# ing916 register map
Vendor: INGChips; Series: ing916xx; File version: 522
CPU: CM4 r0p1, little endian, MPU, FPU, VTOR, 5 interrupt priority bits
Registers are 32-bit, read-write, reset 0x0 unless marked. A register's access mark holds for its fields unless they carry their own. Offsets are from the block's base; [hi:lo] are bit positions; {n}, {i} and the like mark numbered series.

## io_mux_ctrl
Base 0x40006000
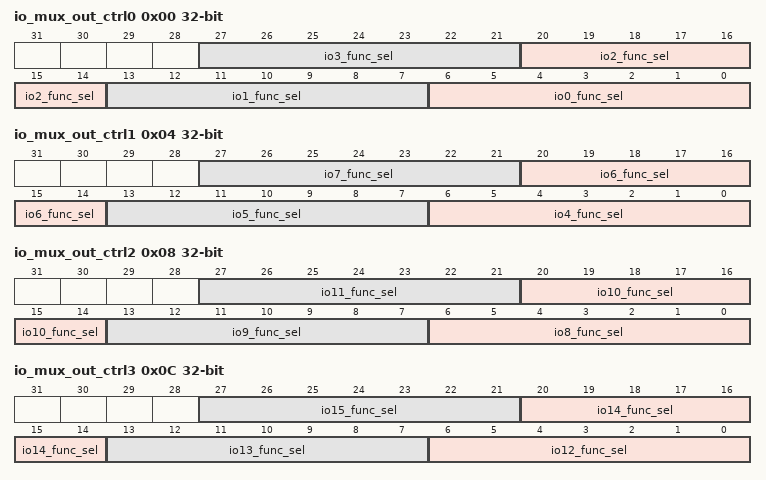
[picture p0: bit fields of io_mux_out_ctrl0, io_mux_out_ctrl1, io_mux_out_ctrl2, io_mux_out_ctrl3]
0x00 io_mux_out_ctrl0 — reg description:
  [7n+6:7n] io{n}_func_sel (n=0..3) — reg description:
0x04 io_mux_out_ctrl1 — reg description:
  [7n-22:7n-28] io{n}_func_sel (n=4..7) — reg description:
0x08 io_mux_out_ctrl2 — reg description:
  [7n-50:7n-56] io{n}_func_sel (n=8..11) — reg description:
0x0C io_mux_out_ctrl3 — reg description:
  [7n-78:7n-84] io{n}_func_sel (n=12..15) — reg description:
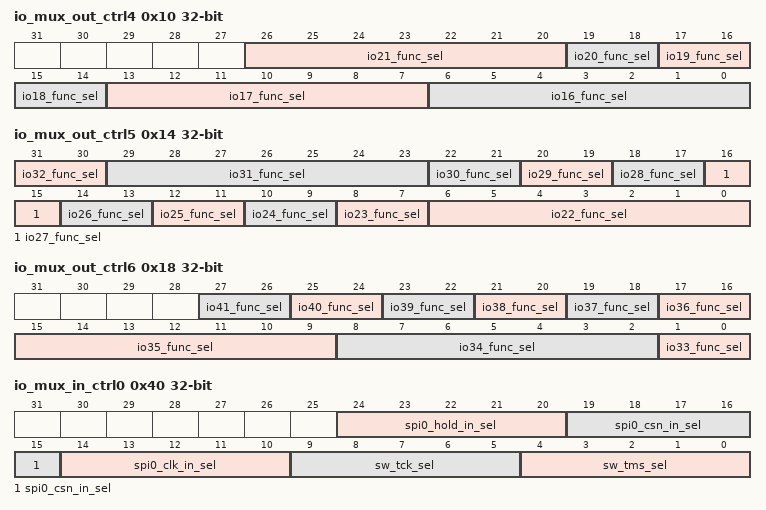
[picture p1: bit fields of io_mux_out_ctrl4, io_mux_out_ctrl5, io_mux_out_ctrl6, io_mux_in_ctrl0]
0x10 io_mux_out_ctrl4 — reg description:
  [26:20] io21_func_sel — reg description:
  [19:18] io20_func_sel — reg description:
  [17:16] io19_func_sel — reg description:
  [15:14] io18_func_sel — reg description:
  [13:7] io17_func_sel — reg description:
  [6:0] io16_func_sel — reg description:
0x14 io_mux_out_ctrl5 — reg description:
  [31:30] io32_func_sel — reg description:
  [29:23] io31_func_sel — reg description:
  [2n-38:2n-39] io{n}_func_sel (n=23..30) — reg description:
  [6:0] io22_func_sel — reg description:
0x18 io_mux_out_ctrl6 — reg description:
  [2n-55:2n-56] io{n}_func_sel (n=36..41) — reg description:
  [15:9] io35_func_sel — reg description:
  [8:2] io34_func_sel — reg description:
  [1:0] io33_func_sel — reg description:
0x40 io_mux_in_ctrl0 — reg description:
  [24:20] spi0_hold_in_sel — reg description:
  [19:15] spi0_csn_in_sel — reg description:
  [14:10] spi0_clk_in_sel — reg description:
  [9:5] sw_tck_sel — reg description:
  [4:0] sw_tms_sel — reg description:
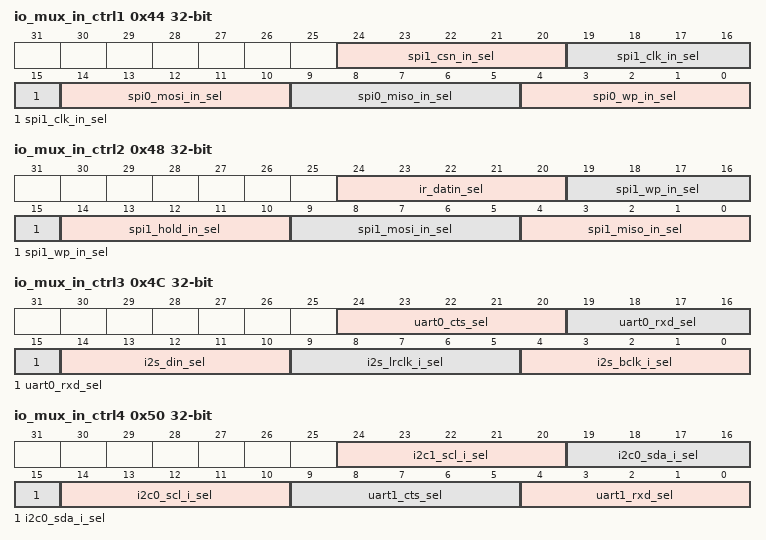
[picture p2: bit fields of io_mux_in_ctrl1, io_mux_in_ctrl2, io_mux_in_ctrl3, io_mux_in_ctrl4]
0x44 io_mux_in_ctrl1 — reg description:
  [24:20] spi1_csn_in_sel — reg description:
  [19:15] spi1_clk_in_sel — reg description:
  [14:10] spi0_mosi_in_sel — reg description:
  [9:5] spi0_miso_in_sel — reg description:
  [4:0] spi0_wp_in_sel — reg description:
0x48 io_mux_in_ctrl2 — reg description:
  [24:20] ir_datin_sel — reg description:
  [19:15] spi1_wp_in_sel — reg description:
  [14:10] spi1_hold_in_sel — reg description:
  [9:5] spi1_mosi_in_sel — reg description:
  [4:0] spi1_miso_in_sel — reg description:
0x4C io_mux_in_ctrl3 — reg description:
  [24:20] uart0_cts_sel — reg description:
  [19:15] uart0_rxd_sel — reg description:
  [14:10] i2s_din_sel — reg description:
  [9:5] i2s_lrclk_i_sel — reg description:
  [4:0] i2s_bclk_i_sel — reg description:
0x50 io_mux_in_ctrl4 — reg description:
  [24:20] i2c1_scl_i_sel — reg description:
  [19:15] i2c0_sda_i_sel — reg description:
  [14:10] i2c0_scl_i_sel — reg description:
  [9:5] uart1_cts_sel — reg description:
  [4:0] uart1_rxd_sel — reg description:
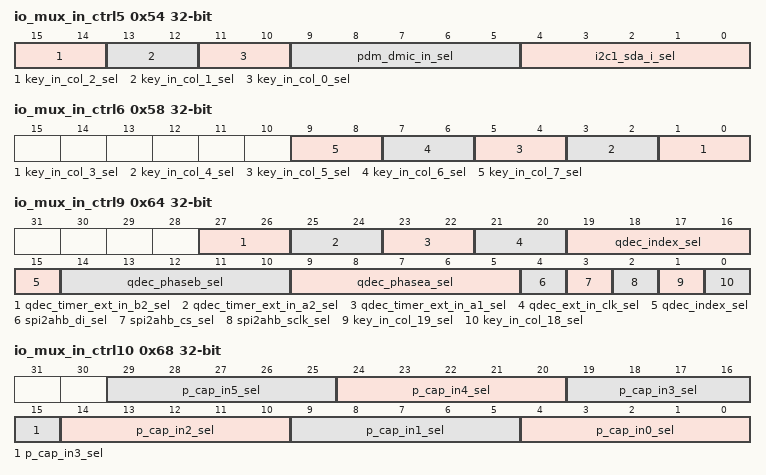
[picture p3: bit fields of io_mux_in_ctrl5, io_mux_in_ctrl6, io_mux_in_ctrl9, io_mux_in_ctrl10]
0x54 io_mux_in_ctrl5 — reg description:
  [15:14] key_in_col_2_sel — reg description:
  [13:12] key_in_col_1_sel — reg description:
  [11:10] key_in_col_0_sel — reg description:
  [9:5] pdm_dmic_in_sel — reg description:
  [4:0] i2c1_sda_i_sel — reg description:
0x58 io_mux_in_ctrl6 — reg description:
  [2n-5:2n-6] key_in_col_{n}_sel (n=3..7) — reg description:
0x5C io_mux_in_ctrl7 — reg description:
0x64 io_mux_in_ctrl9 — reg description:
  [27:26] qdec_timer_ext_in_b2_sel — reg description:
  [25:24] qdec_timer_ext_in_a2_sel — reg description:
  [23:22] qdec_timer_ext_in_a1_sel — reg description:
  [21:20] qdec_ext_in_clk_sel — reg description:
  [19:15] qdec_index_sel — reg description:
  [14:10] qdec_phaseb_sel — reg description:
  [9:5] qdec_phasea_sel — reg description:
  [4] spi2ahb_di_sel — reg description:
  [3] spi2ahb_cs_sel — reg description:
  [2] spi2ahb_sclk_sel — reg description:
  [1] key_in_col_19_sel — reg description:
  [0] key_in_col_18_sel — reg description:
0x68 io_mux_in_ctrl10 — reg description:
  [5n+4:5n] p_cap_in{n}_sel (n=0..5) — reg description:
0x80 io_pe_ctrl0 — reg description:
  [31:0] io_pe_lsb
0x84 io_pe_ctrl1 — reg description:
  [9:0] io_pe_msb
0x88 io_ps_ctrl0 — reg description:
  [31:0] io_ps_lsb
0x8C io_ps_ctrl1 — reg description:
  [9:0] io_ps_msb
0x100 io_mux_is_ctrl0 — reg description:
  [31:0] io_is_lsb
0x104 io_mux_is_ctrl1 — reg description:
  [9:0] io_is_msb
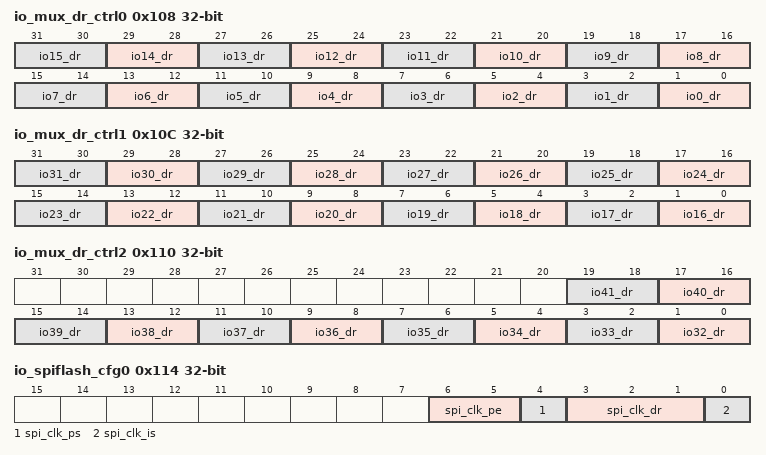
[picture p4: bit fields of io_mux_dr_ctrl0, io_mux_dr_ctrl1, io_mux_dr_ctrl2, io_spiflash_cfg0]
0x108 io_mux_dr_ctrl0 — reg description:
  [2n+1:2n] io{n}_dr (n=0..15) — reg description:
0x10C io_mux_dr_ctrl1 — reg description:
  [2n-31:2n-32] io{n}_dr (n=16..31) — reg description:
0x110 io_mux_dr_ctrl2 — reg description:
  [2n-63:2n-64] io{n}_dr (n=32..41) — reg description:
0x114 io_spiflash_cfg0 — reg description:
  [6:5] spi_clk_pe — reg description:
  [4] spi_clk_ps — reg description:
  [3:1] spi_clk_dr — reg description:
  [0] spi_clk_is — reg description:
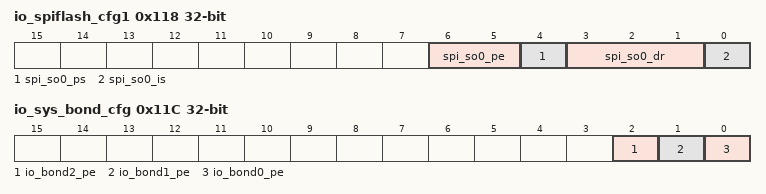
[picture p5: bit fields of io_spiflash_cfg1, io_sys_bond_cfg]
0x118 io_spiflash_cfg1 — reg description:
  [6:5] spi_so0_pe — reg description:
  [4] spi_so0_ps — reg description:
  [3:1] spi_so0_dr — reg description:
  [0] spi_so0_is — reg description:
0x11C io_sys_bond_cfg — reg description:
  [2] io_bond2_pe — reg description:
  [1] io_bond1_pe — reg description:
  [0] io_bond0_pe — reg description:
